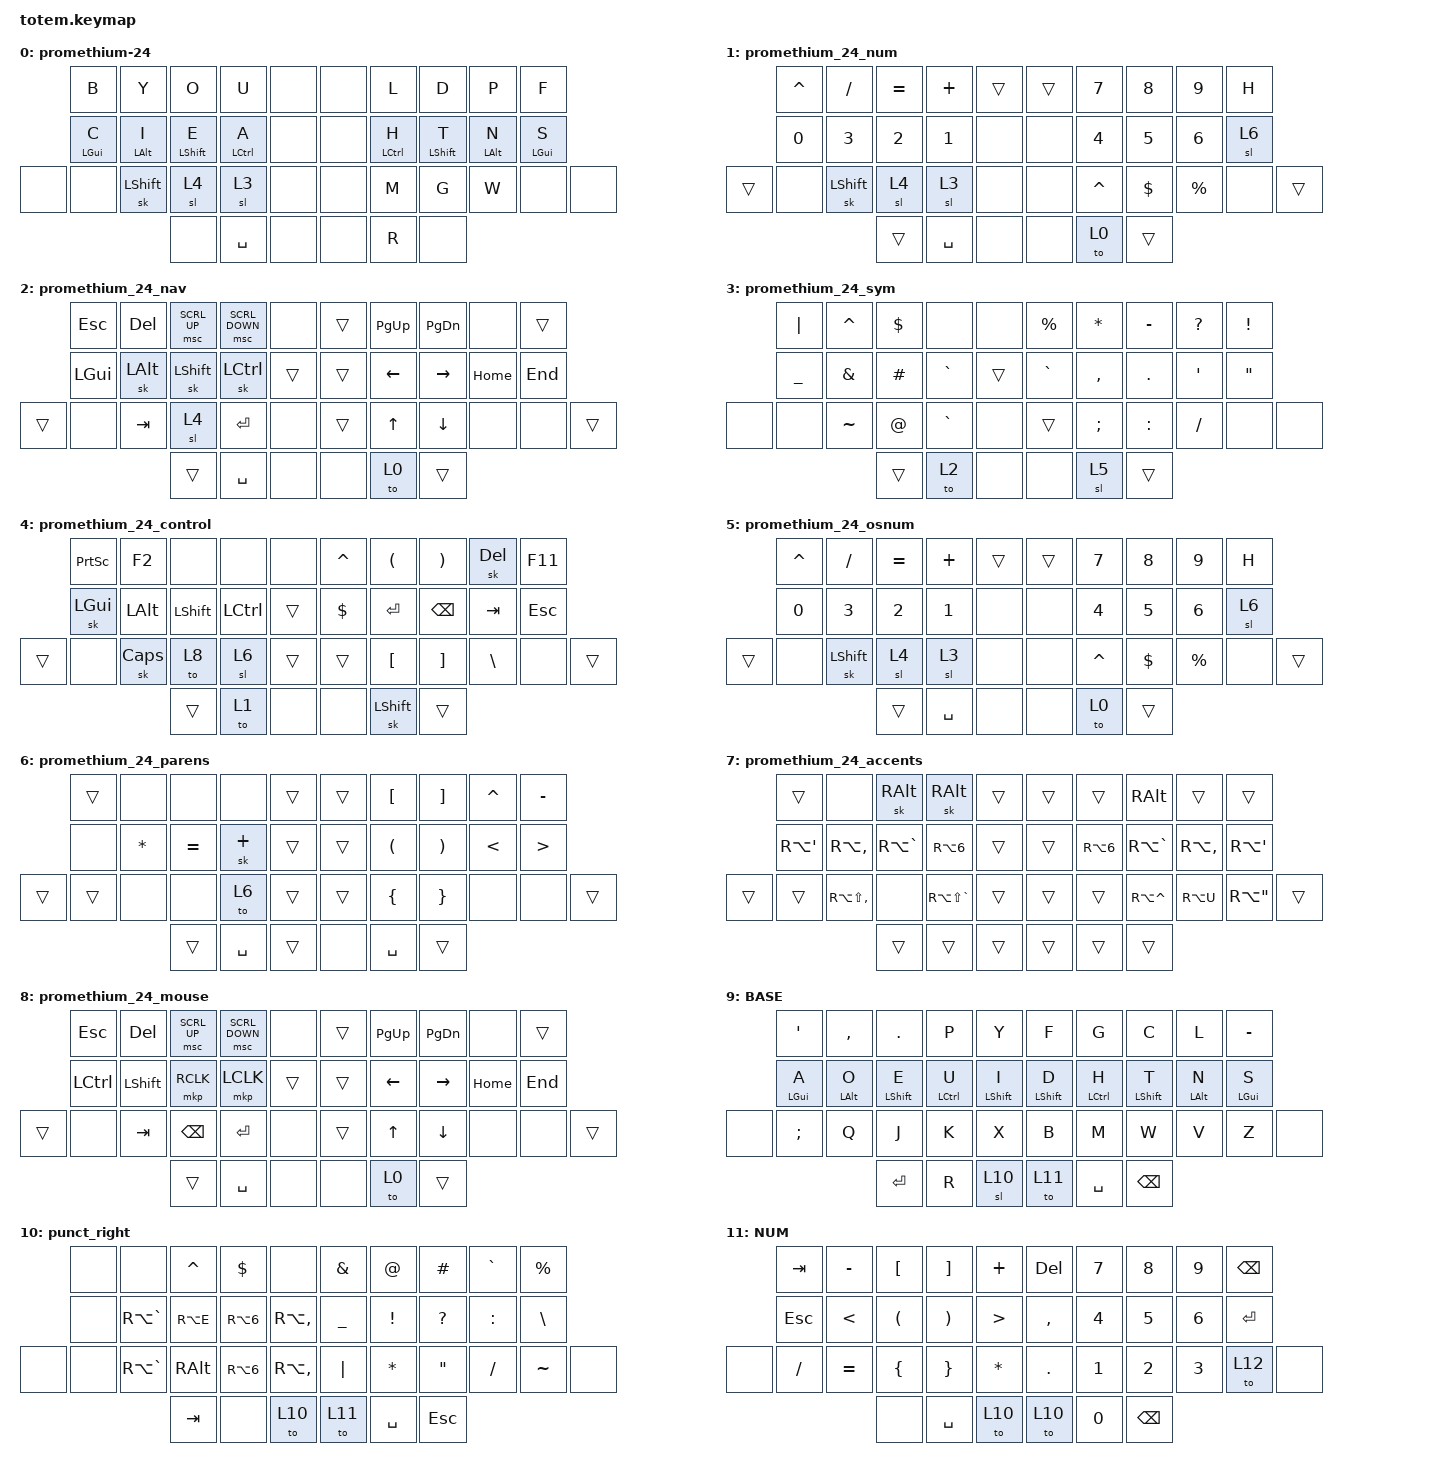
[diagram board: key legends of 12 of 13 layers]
//
//                                                        ▀▀▀▀▀     ▀▀▀▀▀          ▀▀█▀▀
//                                                        ▄▀▀▀▄  ▄  ▄▀▀▀▄  ▄  ▄▀▀▀▄  █  ▄▀▀▀▄
//                                                        █   █  █  █   █  █  █   █  █  █   █
//                                                         ▀▀▀   █   ▀▀▀   █   ▀▀▀   ▀   ▀▀▀
//                                                               █      ▄▄▄█▄▄▄    █   █  
//                                                               ▀      █  █  █     █▄█
//                                                             ▀▀▀▀▀    █  █  █      ▀
//                                                                      ▀  ▀  ▀
//
// ▄▄▄▄▄▄▄▄▄▄▄▄▄▄▄▄▄▄▄▄▄▄▄▄▄▄▄▄▄▄▄▄▄▄▄▄▄▄▄▄▄▄▄▄▄▄▄▄▄▄▄▄▄▄▄▄▄▄▄▄▄▄▄▄▄▄▄▄▄▄▄▄▄▄▄▄▄▄▄▄▄▄▄▄▄▄▄▄▄▄▄▄▄▄▄▄▄▄▄▄▄▄▄▄▄▄▄▄▄▄▄▄▄▄▄▄▄▄▄▄▄▄▄▄▄▄▄▄▄▄▄▄▄▄▄▄▄▄▄▄▄▄▄▄▄▄▄▄▄

#include <behaviors.dtsi>
#include <dt-bindings/zmk/bt.h>
#include <dt-bindings/zmk/keys.h>
#include <dt-bindings/zmk/pointing.h>

#define BASE 0
#define NAV  1
#define SYM  2
#define ADJ  3
#define TVP1 4
#define TVP2 5

&mt {
    quick-tap-ms = <100>;
    global-quick-tap;
    flavor = "tap-preferred";
    tapping-term-ms = <350>;
    hold-trigger-key-positions = <>;
};

&sk { quick-release; };

/ {
    combos {
        compatible = "zmk,combos";

        bluetoothnext {
            bindings = <&bt BT_NXT>;
            key-positions = <22 25>;
        };

        bluetoothprev {
            bindings = <&bt BT_PRV>;
            key-positions = <21 24>;
        };

        bluetoothclr {
            bindings = <&bt BT_CLR>;
            key-positions = <21 25>;
        };

        bluetoothclrall {
            bindings = <&bt BT_CLR_ALL>;
            key-positions = <21 23 25>;
        };

        j {
            bindings = <&kp J>;
            key-positions = <28 27>;
            layers = <0>;
        };

        k {
            bindings = <&kp K>;
            key-positions = <28 29>;
            layers = <0>;
        };

        q {
            bindings = <&kp Q>;
            key-positions = <7 6>;
            layers = <0>;
        };

        z {
            bindings = <&kp Z>;
            key-positions = <7 8>;
            layers = <0>;
        };

        eaigu {
            bindings = <&kp RA(E)>;
            key-positions = <13 12>;
            layers = <0>;
        };

        grave {
            bindings = <&kp RA(GRAVE)>;
            key-positions = <12 11>;
            layers = <0>;
        };

        circ {
            bindings = <&kp RA(NUMBER_6)>;
            key-positions = <3 2>;
            layers = <0>;
        };

        cedille {
            bindings = <&kp RA(COMMA)>;
            key-positions = <2 1>;
            layers = <0>;
        };

        letter-v {
            bindings = <&kp V>;
            key-positions = <16 17>;
        };

        letter-x {
            bindings = <&kp X>;
            key-positions = <17 18>;
        };
    };

    macros {
        frtaandroid: fra {
            compatible = "zmk,behavior-macro";
            #binding-cells = <0>;
            bindings = <&kp GRAVE &kp A>;
            label = "FRA";
        };

        fre: fre {
            compatible = "zmk,behavior-macro";
            #binding-cells = <0>;
            bindings = <&kp RA(GRAVE) &kp E>;
            label = "FRE";
        };

        frseandroid: freandroid {
            compatible = "zmk,behavior-macro";
            #binding-cells = <0>;
            bindings = <&kp GRAVE &kp E>;
            label = "FREANDROID";
        };

        fru: fru {
            compatible = "zmk,behavior-macro";
            #binding-cells = <0>;
            bindings = <&kp RA(GRAVE) &kp U>;
            label = "FRU";
        };

        frzuandroid: fruandroid {
            compatible = "zmk,behavior-macro";
            #binding-cells = <0>;
            bindings = <&kp GRAVE &kp U>;
            label = "FRUANDROID";
        };

        frza: frza {
            compatible = "zmk,behavior-macro";
            #binding-cells = <0>;
            bindings = <&kp RA(GRAVE) &kp A>;
            label = "FRZA";
        };
    };

    behaviors {
        hml: hml {
            compatible = "zmk,behavior-hold-tap";
            label = "HML";
            bindings = <&kp>, <&kp>;

            #binding-cells = <2>;
            tapping-term-ms = <250>;
            flavor = "balanced";
            hold-trigger-key-positions = <27 28 29 30 31 19 9 18 8 7 17 16 6 5 15 37 36 26 35>;
            quick-tap-ms = <175>;
            require-prior-idle-ms = <150>;
            hold-trigger-on-release;
        };

        hmr: hmr {
            compatible = "zmk,behavior-hold-tap";
            label = "HMR";
            bindings = <&kp>, <&kp>;

            #binding-cells = <2>;
            tapping-term-ms = <250>;
            flavor = "balanced";
            hold-trigger-key-positions = <20 21 32 33 34 0 1 2 3 4 10 11 12 13 14 20 21 22 23 24 25 32 33 34>;
            require-prior-idle-ms = <150>;
            quick-tap-ms = <175>;
            hold-trigger-on-release;
        };

        ltl: ltl {
            compatible = "zmk,behavior-hold-tap";
            label = "LTL";
            bindings = <&mo>, <&kp>;

            #binding-cells = <2>;
            tapping-term-ms = <250>;
            flavor = "balanced";
            hold-trigger-key-positions = <27 28 29 30 31 19 9 18 8 7 17 16 6 5 15 37 36 26 35>;
            quick-tap-ms = <175>;
            require-prior-idle-ms = <150>;
            hold-trigger-on-release;
        };

        ltr: ltr {
            compatible = "zmk,behavior-hold-tap";
            label = "LTR";
            bindings = <&mo>, <&kp>;

            #binding-cells = <2>;
            tapping-term-ms = <250>;
            flavor = "balanced";
            hold-trigger-key-positions = <20 21 32 33 34 0 1 2 3 4 10 11 12 13 14 20 21 22 23 24 25 32 33 34>;
            require-prior-idle-ms = <150>;
            quick-tap-ms = <175>;
            hold-trigger-on-release;
        };

        copypaste: copypaste {
            compatible = "zmk,behavior-tap-dance";
            label = "COPYPASTE";
            #binding-cells = <0>;
            bindings = <&kp LC(C)>, <&mt LC(V) LC(X)>;
        };

        repeat_sl: repeat_sl {
            compatible = "zmk,behavior-hold-tap";
            label = "REPEAT_SL";
            bindings = <&sl>, <&key_repeat>;

            #binding-cells = <2>;
            tapping-term-ms = <150>;
            flavor = "balanced";
        };

        comma_shift_tap: comma_shift_tap {
            compatible = "zmk,behavior-tap-dance";
            label = "COMMA_SHIFT_TAP";
            #binding-cells = <0>;
            bindings = <&sk LEFT_SHIFT>, <&kp COMMA>;
        };

        comma_shift_hold: comma_shift_hold {
            compatible = "zmk,behavior-hold-tap";
            label = "COMMA_SHIFT_HOLD";
            bindings = <&kp>, <&sk>;

            #binding-cells = <2>;
            tapping-term-ms = <150>;
            flavor = "balanced";
        };

        hold_sl: hold_sl {
            compatible = "zmk,behavior-hold-tap";
            label = "HOLD_SL";
            bindings = <&to>, <&sl>;

            #binding-cells = <2>;
            tapping-term-ms = <150>;
            flavor = "balanced";
        };

        sltol1: sltol1 {
            compatible = "zmk,behavior-tap-dance";
            label = "SLTOL1";
            #binding-cells = <0>;
            bindings = <&sl 10>, <&to 10>;
        };

        hmkl: hmkl {
            compatible = "zmk,behavior-hold-tap";
            label = "HMKL";
            bindings = <&kp>, <&mkp>;

            #binding-cells = <2>;
            tapping-term-ms = <250>;
            flavor = "balanced";
            hold-trigger-key-positions = <27 28 29 30 31 19 9 18 8 7 17 16 6 5 15 37 36 26 35>;
            quick-tap-ms = <175>;
            require-prior-idle-ms = <150>;
            hold-trigger-on-release;
        };
    };

    keymap {
        compatible = "zmk,keymap";

        // ▄▄▄▄▄▄▄▄▄▄▄▄▄▄▄▄▄▄▄▄▄▄▄▄▄▄▄▄▄▄▄▄▄▄▄▄▄▄▄▄▄▄▄▄▄▄▄▄▄▄▄▄▄▄▄▄▄▄▄▄▄▄▄▄▄▄▄▄▄▄▄▄▄▄▄▄▄▄▄▄▄▄▄▄▄▄▄▄▄▄▄▄▄▄▄▄▄▄▄▄▄▄▄▄▄▄▄▄▄▄▄▄▄▄▄▄▄▄▄▄▄▄▄▄▄▄▄▄▄▄▄▄▄▄▄▄▄▄▄▄▄▄▄▄▄▄▄▄▄

        promethium_24 {
            label = "promethium-24";
            bindings = <
       &kp B            &kp Y            &kp O              &kp U                &none    &none  &kp L                &kp D              &kp P            &kp F
       &hml LEFT_GUI C  &hml LEFT_ALT I  &hml LEFT_SHIFT E  &hml LEFT_CONTROL A  &none    &none  &hmr LEFT_CONTROL H  &hmr LEFT_SHIFT T  &hmr LEFT_ALT N  &hml LEFT_GUI S
&none  &none            &sk LEFT_SHIFT   &sl 4              &sl 3                &none    &none  &kp M                &kp G              &kp W            &none            &none
                                         &none              &kp SPACE            &none    &none  &kp R                &none
            >;
        };

        promethium_24_num {
            bindings = <
        &kp CARET  &kp SLASH       &kp EQUAL  &kp PLUS      &trans    &trans  &kp N7     &kp N8      &kp N9       &kp H
        &kp N0     &kp NUMBER_3    &kp N2     &kp NUMBER_1  &none     &none   &kp N4     &kp N5      &kp N6       &sl 6
&trans  &none      &sk LEFT_SHIFT  &sl 4      &sl 3         &none     &none   &kp CARET  &kp DOLLAR  &kp PERCENT  &none  &trans
                                   &trans     &kp SPACE     &none     &none   &to 0      &trans
            >;
        };

        promethium_24_nav {
            bindings = <
        &kp ESCAPE    &kp DELETE    &msc SCRL_UP    &msc SCRL_DOWN    &none     &trans  &kp PAGE_UP   &kp PAGE_DOWN  &none     &trans
        &kp LEFT_GUI  &sk LEFT_ALT  &sk LEFT_SHIFT  &sk LEFT_CONTROL  &trans    &trans  &kp LEFT      &kp RIGHT      &kp HOME  &kp END
&trans  &none         &kp TAB       &sl 4           &kp ENTER         &none     &trans  &kp UP_ARROW  &kp DOWN       &none     &none    &trans
                                    &trans          &kp SPACE         &none     &none   &to 0         &trans
            >;
        };

        promethium_24_sym {
            bindings = <
       &kp PIPE   &kp CARET  &kp DOLLAR  &none      &none     &kp PERCENT  &kp ASTRK  &kp MINUS  &kp QUESTION  &kp EXCL
       &kp UNDER  &kp AMPS   &kp HASH    &kp GRAVE  &trans    &kp GRAVE    &kp COMMA  &kp DOT    &kp SQT       &kp DOUBLE_QUOTES
&none  &none      &kp TILDE  &kp AT      &kp GRAVE  &none     &trans       &kp SEMI   &kp COLON  &kp SLASH     &none              &none
                             &trans      &to 2      &none     &none        &sl 5      &trans
            >;
        };

        promethium_24_control {
            bindings = <
        &kp PRINTSCREEN  &kp F2        &none           &none             &none     &kp CARET   &kp LEFT_PARENTHESIS  &kp RIGHT_PARENTHESIS  &sk DELETE     &kp F11
        &sk LEFT_GUI     &kp LEFT_ALT  &kp LEFT_SHIFT  &kp LEFT_CONTROL  &trans    &kp DOLLAR  &kp ENTER             &kp BACKSPACE          &kp TAB        &kp ESCAPE
&trans  &none            &sk CAPSLOCK  &to 8           &sl 6             &trans    &trans      &kp LEFT_BRACKET      &kp RIGHT_BRACKET      &kp BACKSLASH  &none       &trans
                                       &trans          &to 1             &none     &none       &sk LEFT_SHIFT        &trans
            >;
        };

        promethium_24_osnum {
            bindings = <
        &kp CARET  &kp SLASH       &kp EQUAL  &kp PLUS      &trans    &trans  &kp N7     &kp N8      &kp N9       &kp H
        &kp N0     &kp NUMBER_3    &kp N2     &kp NUMBER_1  &none     &none   &kp N4     &kp N5      &kp N6       &sl 6
&trans  &none      &sk LEFT_SHIFT  &sl 4      &sl 3         &none     &none   &kp CARET  &kp DOLLAR  &kp PERCENT  &none  &trans
                                   &trans     &kp SPACE     &none     &none   &to 0      &trans
            >;
        };

        promethium_24_parens {
            bindings = <
        &trans  &none      &none      &none      &trans    &trans  &kp LEFT_BRACKET      &kp RIGHT_BRACKET      &kp CARET      &kp MINUS
        &none   &kp ASTRK  &kp EQUAL  &sk PLUS   &trans    &trans  &kp LEFT_PARENTHESIS  &kp RIGHT_PARENTHESIS  &kp LESS_THAN  &kp GREATER_THAN
&trans  &trans  &none      &none      &to 6      &trans    &trans  &kp LEFT_BRACE        &kp RIGHT_BRACE        &none          &none             &trans
                           &trans     &kp SPACE  &trans    &none   &kp SPACE             &trans
            >;
        };

        promethium_24_accents {
            bindings = <
        &trans       &none              &sk RALT       &sk RALT           &trans    &trans  &trans            &kp RIGHT_ALT  &trans         &trans
        &kp RA(SQT)  &kp RA(COMMA)      &kp RA(GRAVE)  &kp RA(NUMBER_6)   &trans    &trans  &kp RA(NUMBER_6)  &kp RA(GRAVE)  &kp RA(COMMA)  &kp RA(APOS)
&trans  &trans       &kp RA(LS(COMMA))  &none          &kp RA(LS(GRAVE))  &trans    &trans  &trans            &kp RA(CARET)  &kp RA(U)      &kp RA(DOUBLE_QUOTES)  &trans
                                        &trans         &trans             &trans    &trans  &trans            &trans
            >;
        };

        promethium_24_mouse {
            bindings = <
        &kp ESCAPE        &kp DELETE      &msc SCRL_UP   &msc SCRL_DOWN  &none     &trans  &kp PAGE_UP   &kp PAGE_DOWN  &none     &trans
        &kp LEFT_CONTROL  &kp LEFT_SHIFT  &mkp RCLK      &mkp LCLK       &trans    &trans  &kp LEFT      &kp RIGHT      &kp HOME  &kp END
&trans  &none             &kp TAB         &kp BACKSPACE  &kp ENTER       &none     &trans  &kp UP_ARROW  &kp DOWN       &none     &none    &trans
                                          &trans         &kp SPACE       &none     &none   &to 0         &trans
            >;
        };

        base_layer {
            // ┏━━━━━━━━━━━━━━━━━━━━━━━━━━━━━━━━━━━━━━━┓

            label = "BASE";

            // ┗━━━━━━━━━━━━━━━━━━━━━━━━━━━━━━━━━━━━━━━┛
            //             ┏━━━━━━━━━━━┳━━━━━━━━━━━┳━━━━━━━━━━━┳━━━━━━━━━━━┳━━━━━━━━━━━┓   ┏━━━━━━━━━━━┳━━━━━━━━━━━┳━━━━━━━━━━━┳━━━━━━━━━━━┳━━━━━━━━━━━┓
            //             ┃     Q     ┃     W     ┃     F     ┃     P     ┃     G     ┃   ┃     J     ┃     L     ┃     U     ┃     Y     ┃     ;     ┃
            //             ┣━━━━━━━━━━━╋━━━━━━━━━━━╋━━━━━━━━━━━╋━━━━━━━━━━━╋━━━━━━━━━━━┫   ┣━━━━━━━━━━━╋━━━━━━━━━━━╋━━━━━━━━━━━╋━━━━━━━━━━━╋━━━━━━━━━━━┫
            //             ┃     A     ┃     R     ┃     S     ┃     T     ┃     D     ┃   ┃     H     ┃     N     ┃     E     ┃     I     ┃     O     ┃
            // ┏━━━━━━━━━━━╋━━━━━━━━━━━╋━━━━━━━━━━━╋━━━━━━━━━━━╋━━━━━━━━━━━╋━━━━━━━━━━━┫   ┣━━━━━━━━━━━╋━━━━━━━━━━━╋━━━━━━━━━━━╋━━━━━━━━━━━╋━━━━━━━━━━━╋━━━━━━━━━━━┓
            // ┃     Q     ┃     Z     ┃     X     ┃     C     ┃     V     ┃     B     ┃   ┃     K     ┃     M     ┃     ,     ┃     .     ┃     /     ┃     \     ┃
            // ┗━━━━━━━━━━━┻━━━━━━━━━━━┻━━━━━━━━━━━╋━━━━━━━━━━━╋━━━━━━━━━━━╋━━━━━━━━━━━┫   ┣━━━━━━━━━━━╋━━━━━━━━━━━╋━━━━━━━━━━━╋━━━━━━━━━━━┻━━━━━━━━━━━┻━━━━━━━━━━━┛
            //                                     ┃    DEL    ┃    TAB    ┃    SPC    ┃   ┃   ENTER   ┃           ┃   BSPC    ┃
            //                                     ┗━━━━━━━━━━━┻━━━━━━━━━━━┻━━━━━━━━━━━┛   ┗━━━━━━━━━━━┻━━━━━━━━━━━┻━━━━━━━━━━━┛

            bindings = <
       &kp SQT          &kp COMMA        &kp PERIOD         &kp P                &kp Y                &kp F              &kp G                &kp C              &kp L            &kp MINUS
       &hml LEFT_GUI A  &hml LEFT_ALT O  &hml LEFT_SHIFT E  &hml LEFT_CONTROL U  &hml LEFT_SHIFT I    &hml LEFT_SHIFT D  &hmr LEFT_CONTROL H  &hmr LEFT_SHIFT T  &hmr LEFT_ALT N  &hmr LEFT_GUI S
&none  &kp SEMICOLON    &kp Q            &kp J              &kp K                &kp X                &kp B              &kp M                &kp W              &kp V            &kp Z            &none
                                         &kp ENTER          &kp R                &sl 10               &to 11             &kp SPACE            &kp BACKSPACE
            >;
        };

        punctuation_layer_right {
            label = "punct_right";
            bindings = <
       &none  &none          &kp CARET      &kp DOLLAR        &none            &kp AMPS   &kp AT           &kp HASH           &kp GRAVE  &kp PERCENT
       &none  &kp RA(GRAVE)  &kp RA(E)      &kp RA(NUMBER_6)  &kp RA(COMMA)    &kp UNDER  &kp EXCLAMATION  &kp QUESTION       &kp COLON  &kp BACKSLASH
&none  &none  &kp RA(GRAVE)  &kp RIGHT_ALT  &kp RA(NUMBER_6)  &kp RA(COMMA)    &kp PIPE   &kp ASTRK        &kp DOUBLE_QUOTES  &kp SLASH  &kp TILDE      &none
                             &kp TAB        &none             &to 10           &to 11     &kp SPACE        &kp ESCAPE
            >;
        };

        num_layer {
            // ┏━━━━━━━━━━━━━━━━━━━━━━━━━━━━━━━━━━━━━━━┓

            label = "NUM";

            // ┗━━━━━━━━━━━━━━━━━━━━━━━━━━━━━━━━━━━━━━━┛
            //             ┏━━━━━━━━━━━┳━━━━━━━━━━━┳━━━━━━━━━━━┳━━━━━━━━━━━┳━━━━━━━━━━━┓   ┏━━━━━━━━━━━┳━━━━━━━━━━━┳━━━━━━━━━━━┳━━━━━━━━━━━┳━━━━━━━━━━━┓
            //             ┃   RESET   ┃ BT CLEAR  ┃  OUT TOG  ┃           ┃           ┃   ┃           ┃    F7     ┃    F8     ┃    F9     ┃    F12    ┃
            //             ┣━━━━━━━━━━━╋━━━━━━━━━━━╋━━━━━━━━━━━╋━━━━━━━━━━━╋━━━━━━━━━━━┫   ┣━━━━━━━━━━━╋━━━━━━━━━━━╋━━━━━━━━━━━╋━━━━━━━━━━━╋━━━━━━━━━━━┫
            //             ┃ BOOTLOAD  ┃ BT NEXT   ┃           ┃           ┃           ┃   ┃           ┃    F4     ┃    F5     ┃    F6     ┃    F11    ┃
            // ┏━━━━━━━━━━━╋━━━━━━━━━━━╋━━━━━━━━━━━╋━━━━━━━━━━━╋━━━━━━━━━━━╋━━━━━━━━━━━┫   ┣━━━━━━━━━━━╋━━━━━━━━━━━╋━━━━━━━━━━━╋━━━━━━━━━━━╋━━━━━━━━━━━╋━━━━━━━━━━━┓
            // ┃           ┃           ┃ BT PREV   ┃           ┃           ┃           ┃   ┃           ┃    F1     ┃    F2     ┃    F3     ┃    F10    ┃           ┃
            // ┗━━━━━━━━━━━┻━━━━━━━━━━━┻━━━━━━━━━━━╋━━━━━━━━━━━╋━━━━━━━━━━━╋━━━━━━━━━━━┫   ┣━━━━━━━━━━━╋━━━━━━━━━━━╋━━━━━━━━━━━╋━━━━━━━━━━━┻━━━━━━━━━━━┻━━━━━━━━━━━┛
            //                                     ┃           ┃           ┃           ┃   ┃           ┃           ┃           ┃
            //                                     ┗━━━━━━━━━━━┻━━━━━━━━━━━┻━━━━━━━━━━━┛   ┗━━━━━━━━━━━┻━━━━━━━━━━━┻━━━━━━━━━━━┛

            bindings = <
       &kp TAB     &kp MINUS      &kp LEFT_BRACKET      &kp RIGHT_BRACKET      &kp PLUS            &kp DELETE  &kp N7  &kp N8         &kp N9  &kp BACKSPACE
       &kp ESCAPE  &kp LESS_THAN  &kp LEFT_PARENTHESIS  &kp RIGHT_PARENTHESIS  &kp GREATER_THAN    &kp COMMA   &kp N4  &kp N5         &kp N6  &kp ENTER
&none  &kp SLASH   &kp EQUAL      &kp LEFT_BRACE        &kp RIGHT_BRACE        &kp ASTRK           &kp PERIOD  &kp N1  &kp N2         &kp N3  &to 12         &none
                                  &none                 &kp SPACE              &to 10              &to 10      &kp N0  &kp BACKSPACE
            >;
        };

        nav_layer {
            // ┏━━━━━━━━━━━━━━━━━━━━━━━━━━━━━━━━━━━━━━━┓

            label = "NAV";

            // ┗━━━━━━━━━━━━━━━━━━━━━━━━━━━━━━━━━━━━━━━┛
            //             ┏━━━━━━━━━━━┳━━━━━━━━━━━┳━━━━━━━━━━━┳━━━━━━━━━━━┳━━━━━━━━━━━┓   ┏━━━━━━━━━━━┳━━━━━━━━━━━┳━━━━━━━━━━━┳━━━━━━━━━━━┳━━━━━━━━━━━┓
            //             ┃     !     ┃     @     ┃     #     ┃     $     ┃     %     ┃   ┃     ˆ     ┃     &     ┃     Ü     ┃     '     ┃     "     ┃
            //             ┣━━━━━━━━━━━╋━━━━━━━━━━━╋━━━━━━━━━━━╋━━━━━━━━━━━╋━━━━━━━━━━━┫   ┣━━━━━━━━━━━╋━━━━━━━━━━━╋━━━━━━━━━━━╋━━━━━━━━━━━╋━━━━━━━━━━━┫
            //             ┃     Ä     ┃           ┃    SZ     ┃           ┃           ┃   ┃   MUTE    ┃   YEN     ┃   EURO    ┃  POUND    ┃     Ö     ┃
            // ┏━━━━━━━━━━━╋━━━━━━━━━━━╋━━━━━━━━━━━╋━━━━━━━━━━━╋━━━━━━━━━━━╋━━━━━━━━━━━┫   ┣━━━━━━━━━━━╋━━━━━━━━━━━╋━━━━━━━━━━━╋━━━━━━━━━━━╋━━━━━━━━━━━╋━━━━━━━━━━━┓
            // ┃           ┃  EMAIL1   ┃  EMAIL2   ┃           ┃           ┃           ┃   ┃   VOL-    ┃   VOL+    ┃   LAST    ┃   NEXT    ┃     \     ┃           ┃
            // ┗━━━━━━━━━━━┻━━━━━━━━━━━┻━━━━━━━━━━━╋━━━━━━━━━━━╋━━━━━━━━━━━╋━━━━━━━━━━━┫   ┣━━━━━━━━━━━╋━━━━━━━━━━━╋━━━━━━━━━━━╋━━━━━━━━━━━┻━━━━━━━━━━━┻━━━━━━━━━━━┛
            //                                     ┃           ┃    GIF    ┃    ADJ    ┃   ┃           ┃           ┃           ┃
            //                                     ┗━━━━━━━━━━━┻━━━━━━━━━━━┻━━━━━━━━━━━┛   ┗━━━━━━━━━━━┻━━━━━━━━━━━┻━━━━━━━━━━━┛

            bindings = <
       &kp LC(TAB)          &kp ESCAPE          &kp F2                &kp F11                 &kp F4       &kp PRINTSCREEN  &kp LC(LS(TAB))  &kp LC(TAB)  &kp ENTER      &kp BACKSPACE
       &mt LEFT_GUI ESCAPE  &mt LEFT_ALT LC(N)  &mt LEFT_SHIFT LC(T)  &mt LEFT_CONTROL LC(P)  &kp LC(Y)    &sk HOME         &kp LEFT         &kp RIGHT    &kp END        &kp ENTER
&none  &kp LC(A)            &kp LC(C)           &kp LC(W)             &kp LC(V)               &kp LC(X)    &kp PAGE_UP      &kp UP_ARROW     &kp DOWN     &kp PAGE_DOWN  &to 10         &none
                                                &none                 &kp LEFT_SHIFT          &to 10       &to 11           &kp SPACE        &none
            >;
        };

        // ▄▄▄▄▄▄▄▄▄▄▄▄▄▄▄▄▄▄▄▄▄▄▄▄▄▄▄▄▄▄▄▄▄▄▄▄▄▄▄▄▄▄▄▄▄▄▄▄▄▄▄▄▄▄▄▄▄▄▄▄▄▄▄▄▄▄▄▄▄▄▄▄▄▄▄▄▄▄▄▄▄▄▄▄▄▄▄▄▄▄▄▄▄▄▄▄▄▄▄▄▄▄▄▄▄▄▄▄▄▄▄▄▄▄▄▄▄▄▄▄▄▄▄▄▄▄▄▄▄▄▄▄▄▄▄▄▄▄▄▄▄▄▄▄▄▄▄▄▄
    };
};
